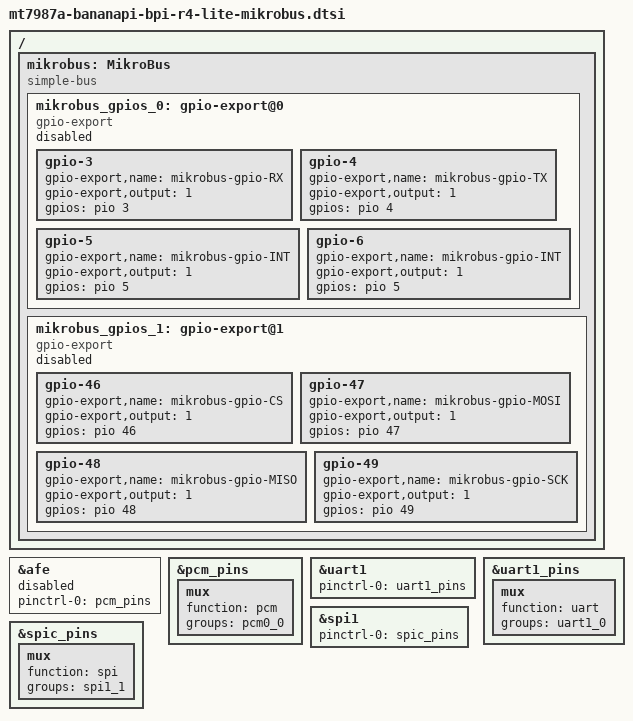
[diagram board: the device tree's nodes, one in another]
// SPDX-License-Identifier: (GPL-2.0 OR MIT)
/*
 * Copyright (C) 2025 MediaTek Inc.
 * Author: Sam.Shih <sam.shih@mediatek.com>
 */

#include <dt-bindings/gpio/gpio.h>

/*
 * --------------- Bananapi Bpi R4 Lite MikroBus ----------------
 * | 9  |                           GPIO7/PWM1              | 8 |
 * | 10 | GPIO6/PCM_FS/UART1_RTS    GPIO5/PCM_CLK/UART1_CTS | 7 |
 * | 11 | GPIO49/SPI1_CS            GPIO3/PCM_DTX/UART1_RXD | 6 |
 * | 12 | GPIO46/SPI1_CLK           GPIO4/PCM_DRX/UART1_TXD | 5 |
 * | 13 | GPIO48/SPI1_MISO          I2C3 SCL (PCA9548)      | 4 |
 * | 14 | GPIO47/SPI1_MOSI          I2C3 SDA (PCA9548)      | 3 |
 * | 15 | +3.3V                     +5V                     | 2 |
 * | 16 | GND                       GND                     | 1 |
 * --------------------------------------------------------------
 */

/ {
	mikrobus: MikroBus {
		compatible = "simple-bus";

		/* MikroBus pins 5,6,7,8 as GPIOs */
		mikrobus_gpios_0: gpio-export@0 {
			compatible = "gpio-export";
			status = "disabled";

			gpio-3 {
				gpio-export,name = "mikrobus-gpio-RX";
				gpio-export,output = <1>;
				gpios = <&pio 3 GPIO_ACTIVE_HIGH>;
			};

			gpio-4 {
				gpio-export,name = "mikrobus-gpio-TX";
				gpio-export,output = <1>;
				gpios = <&pio 4 GPIO_ACTIVE_HIGH>;
			};

			gpio-5 {
				gpio-export,name = "mikrobus-gpio-INT";
				gpio-export,output = <1>;
				gpios = <&pio 5 GPIO_ACTIVE_HIGH>;
			};

			gpio-6 {
				gpio-export,name = "mikrobus-gpio-INT";
				gpio-export,output = <1>;
				gpios = <&pio 5 GPIO_ACTIVE_HIGH>;
			};
		};

		/* MikroBus pins 11,12,13,14 as GPIOs */
		mikrobus_gpios_1: gpio-export@1 {
			compatible = "gpio-export";
			status = "disabled";

			gpio-46 {
				gpio-export,name = "mikrobus-gpio-CS";
				gpio-export,output = <1>;
				gpios = <&pio 46 GPIO_ACTIVE_HIGH>;
			};

			gpio-47 {
				gpio-export,name = "mikrobus-gpio-MOSI";
				gpio-export,output = <1>;
				gpios = <&pio 47 GPIO_ACTIVE_HIGH>;
			};

			gpio-48 {
				gpio-export,name = "mikrobus-gpio-MISO";
				gpio-export,output = <1>;
				gpios = <&pio 48 GPIO_ACTIVE_HIGH>;
			};

			gpio-49 {
				gpio-export,name = "mikrobus-gpio-SCK";
				gpio-export,output = <1>;
				gpios = <&pio 49 GPIO_ACTIVE_HIGH>;
			};
		};
	};
};

/* MikroBus pins 3,4 as I2C3 (Provided by PCA9548 i2c-mux) */
/* Please refer to &imux2_MikroBus device tree node */

/* MikroBus pins 5,6,7,10 as PCM function */
&afe {
	pinctrl-names = "default";
	pinctrl-0 = <&pcm_pins>;
	status = "disabled";
};

&pcm_pins {
	mux {
		function = "pcm";
		groups = "pcm0_0";
	};
};

/* MikroBus pins 5,6,7,10 as UART1 function */
&uart1 {
	pinctrl-names = "default";
	pinctrl-0 = <&uart1_pins>;
	status = "okay";
};

&uart1_pins {
	mux {
		function = "uart";
		groups = "uart1_0";
	};
};

/* MikroBus pins 8 as PWM1 */
/* Please refer to &pwm device tree node */

/* MikroBus pins 11,12,13,14 as SPI1 function */
&spi1 {
	pinctrl-names = "default";
	pinctrl-0 = <&spic_pins>;
	status = "okay";
};

&spic_pins {
	mux {
		function = "spi";
		groups = "spi1_1";
	};
};
